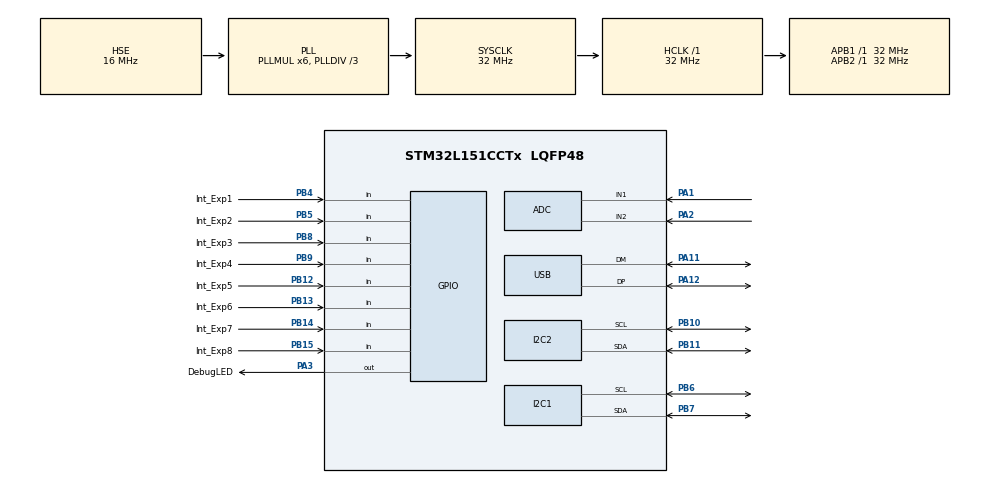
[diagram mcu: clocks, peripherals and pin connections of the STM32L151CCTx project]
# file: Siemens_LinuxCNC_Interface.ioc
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ADC.Channel-0\#ChannelRegularConversion=ADC_CHANNEL_1
ADC.NbrOfConversionFlag=1
ADC.Rank-0\#ChannelRegularConversion=1
ADC.SamplingTime-0\#ChannelRegularConversion=ADC_SAMPLETIME_4CYCLES
I2C2.I2C_Mode=I2C_Standard
Mcu.Family=STM32L1
Mcu.Name=STM32L151CCTx
Mcu.Package=LQFP48
NVIC.PriorityGroup=NVIC_PRIORITYGROUP_4
NVIC.TIM3_IRQn=true\:0\:0\:false\:false\:true\:true\:true\:true
NVIC.USB_LP_IRQn=true\:0\:0\:false\:false\:true\:false\:true\:true
PA1.Mode=IN1
PA1.Signal=ADC_IN1
PA11.Mode=Device
PA11.Signal=USB_DM
PA12.Mode=Device
PA12.Signal=USB_DP
PA13.Mode=JTAG_4_pins
PA13.Signal=SYS_JTMS-SWDIO
PA14.Mode=JTAG_4_pins
PA14.Signal=SYS_JTCK-SWCLK
PA15.Mode=JTAG_4_pins
PA15.Signal=SYS_JTDI
PA2.Mode=IN2
PA2.Signal=ADC_IN2
PA3.GPIO_Label=DebugLED
PA3.Signal=GPIO_Output
PB10.Mode=I2C
PB10.Signal=I2C2_SCL
PB11.Mode=I2C
PB11.Signal=I2C2_SDA
PB12.GPIO_Label=Int_Exp5
PB12.Signal=GPIO_Input
PB13.GPIO_Label=Int_Exp6
PB13.Signal=GPIO_Input
PB14.GPIO_Label=Int_Exp7
PB14.Signal=GPIO_Input
PB15.GPIO_Label=Int_Exp8
PB15.Signal=GPIO_Input
PB3.Mode=JTAG_4_pins
PB3.Signal=SYS_JTDO-TRACESWO
PB4.GPIO_Label=Int_Exp1
PB4.Signal=GPIO_Input
PB5.GPIO_Label=Int_Exp2
PB5.Signal=GPIO_Input
PB6.Mode=I2C
PB6.Signal=I2C1_SCL
PB7.Mode=I2C
PB7.Signal=I2C1_SDA
PB8.GPIO_Label=Int_Exp3
PB8.Signal=GPIO_Input
PB9.GPIO_Label=Int_Exp4
PB9.Signal=GPIO_Input
PH0-OSC_IN.Mode=HSE-External-Oscillator
PH0-OSC_IN.Signal=RCC_OSC_IN
PH1-OSC_OUT.Mode=HSE-External-Oscillator
PH1-OSC_OUT.Signal=RCC_OSC_OUT
ProjectManager.HeapSize=0x200
ProjectManager.StackSize=0x400
ProjectManager.TargetToolchain=STM32CubeIDE
RCC.48MHZClocksFreq_Value=48000000
RCC.AHBFreq_Value=32000000
RCC.APB1Freq_Value=32000000
RCC.APB1TimFreq_Value=32000000
RCC.APB2Freq_Value=32000000
RCC.APB2TimFreq_Value=32000000
RCC.HCLKFreq_Value=32000000
RCC.HSE_VALUE=16000000
RCC.HSI_VALUE=16000000
RCC.LSE_VALUE=32768
RCC.MSI_VALUE=2097000
RCC.PLLDIV=RCC_PLL_DIV3
RCC.PLLMUL=RCC_PLL_MUL6
RCC.SYSCLKFreq_VALUE=32000000
RCC.SYSCLKSource=RCC_SYSCLKSOURCE_PLLCLK
RCC.VCOOutputFreq_Value=96000000
TIM3.AutoReloadPreload=TIM_AUTORELOAD_PRELOAD_ENABLE
TIM3.Period=5000
TIM3.Prescaler=3200
USB_DEVICE.CLASS_NAME_FS=CDC
USB_DEVICE.LANGID_STRING=1031
USB_DEVICE.MANUFACTURER_STRING=Patrick Lermer
USB_DEVICE.PRODUCT_STRING_CDC_FS=Siemens Interface Virtual ComPort
USB_DEVICE.VirtualMode=Cdc
USB_DEVICE.VirtualModeFS=Cdc_FS
VP_TIM3_VS_ClockSourceINT.Mode=Internal
VP_USB_DEVICE_VS_USB_DEVICE_CDC_FS.Mode=CDC_FS
board=custom

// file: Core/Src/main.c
/* USER CODE BEGIN Header */
/**
  ******************************************************************************
  * @file           : main.c
  * @brief          : Main program body
  ******************************************************************************
  * @attention
  *
  * Copyright (c) 2025 STMicroelectronics.
  * All rights reserved.
  *
  * This software is licensed under terms that can be found in the LICENSE file
  * in the root directory of this software component.
  * If no LICENSE file comes with this software, it is provided AS-IS.
  *
  ******************************************************************************
  */
/* USER CODE END Header */
#include "main.h"
#include "usb_device.h"

/* USER CODE BEGIN Includes */
#include "pca9555.c"
/* USER CODE END Includes */

ADC_HandleTypeDef hadc;

I2C_HandleTypeDef hi2c1;
I2C_HandleTypeDef hi2c2;

TIM_HandleTypeDef htim3;

void SystemClock_Config(void);
static void MX_GPIO_Init(void);
static void MX_ADC_Init(void);
static void MX_I2C1_Init(void);
static void MX_I2C2_Init(void);
static void MX_TIM3_Init(void);

int main(void)
{

  /* MCU Configuration--------------------------------------------------------*/

  /* Reset of all peripherals, Initializes the Flash interface and the Systick. */
  HAL_Init();

  /* Configure the system clock */
  SystemClock_Config();

  /* Initialize all configured peripherals */
  MX_GPIO_Init();
  MX_ADC_Init();
  MX_I2C1_Init();
  MX_I2C2_Init();
  MX_USB_DEVICE_Init();
  MX_TIM3_Init();

  /* Infinite loop */
  while (1)
  {

  }
}

void SystemClock_Config(void)
{
  RCC_OscInitTypeDef RCC_OscInitStruct = {0};
  RCC_ClkInitTypeDef RCC_ClkInitStruct = {0};

  /** Configure the main internal regulator output voltage
  */
  __HAL_PWR_VOLTAGESCALING_CONFIG(PWR_REGULATOR_VOLTAGE_SCALE1);

  /** Initializes the RCC Oscillators according to the specified parameters
  * in the RCC_OscInitTypeDef structure.
  */
  RCC_OscInitStruct.OscillatorType = RCC_OSCILLATORTYPE_HSI|RCC_OSCILLATORTYPE_HSE;
  RCC_OscInitStruct.HSEState = RCC_HSE_ON;
  RCC_OscInitStruct.HSIState = RCC_HSI_ON;
  RCC_OscInitStruct.HSICalibrationValue = RCC_HSICALIBRATION_DEFAULT;
  RCC_OscInitStruct.PLL.PLLState = RCC_PLL_ON;
  RCC_OscInitStruct.PLL.PLLSource = RCC_PLLSOURCE_HSE;
  RCC_OscInitStruct.PLL.PLLMUL = RCC_PLL_MUL6;
  RCC_OscInitStruct.PLL.PLLDIV = RCC_PLL_DIV3;
  if (HAL_RCC_OscConfig(&RCC_OscInitStruct) != HAL_OK)
  {
    Error_Handler();
  }

  /** Initializes the CPU, AHB and APB buses clocks
  */
  RCC_ClkInitStruct.ClockType = RCC_CLOCKTYPE_HCLK|RCC_CLOCKTYPE_SYSCLK
                              |RCC_CLOCKTYPE_PCLK1|RCC_CLOCKTYPE_PCLK2;
  RCC_ClkInitStruct.SYSCLKSource = RCC_SYSCLKSOURCE_PLLCLK;
  RCC_ClkInitStruct.AHBCLKDivider = RCC_SYSCLK_DIV1;
  RCC_ClkInitStruct.APB1CLKDivider = RCC_HCLK_DIV1;
  RCC_ClkInitStruct.APB2CLKDivider = RCC_HCLK_DIV1;

  if (HAL_RCC_ClockConfig(&RCC_ClkInitStruct, FLASH_LATENCY_1) != HAL_OK)
  {
    Error_Handler();
  }
}

static void MX_ADC_Init(void)
{

  ADC_ChannelConfTypeDef sConfig = {0};

  /** Configure the global features of the ADC (Clock, Resolution, Data Alignment and number of conversion)
  */
  hadc.Instance = ADC1;
  hadc.Init.ClockPrescaler = ADC_CLOCK_ASYNC_DIV1;
  hadc.Init.Resolution = ADC_RESOLUTION_12B;
  hadc.Init.DataAlign = ADC_DATAALIGN_RIGHT;
  hadc.Init.ScanConvMode = ADC_SCAN_DISABLE;
  hadc.Init.EOCSelection = ADC_EOC_SEQ_CONV;
  hadc.Init.LowPowerAutoWait = ADC_AUTOWAIT_DISABLE;
  hadc.Init.LowPowerAutoPowerOff = ADC_AUTOPOWEROFF_DISABLE;
  hadc.Init.ChannelsBank = ADC_CHANNELS_BANK_A;
  hadc.Init.ContinuousConvMode = DISABLE;
  hadc.Init.NbrOfConversion = 1;
  hadc.Init.DiscontinuousConvMode = DISABLE;
  hadc.Init.ExternalTrigConv = ADC_SOFTWARE_START;
  hadc.Init.ExternalTrigConvEdge = ADC_EXTERNALTRIGCONVEDGE_NONE;
  hadc.Init.DMAContinuousRequests = DISABLE;
  if (HAL_ADC_Init(&hadc) != HAL_OK)
  {
    Error_Handler();
  }

  /** Configure for the selected ADC regular channel its corresponding rank in the sequencer and its sample time.
  */
  sConfig.Channel = ADC_CHANNEL_1;
  sConfig.Rank = ADC_REGULAR_RANK_1;
  sConfig.SamplingTime = ADC_SAMPLETIME_4CYCLES;
  if (HAL_ADC_ConfigChannel(&hadc, &sConfig) != HAL_OK)
  {
    Error_Handler();
  }

}

static void MX_I2C1_Init(void)
{

  hi2c1.Instance = I2C1;
  hi2c1.Init.ClockSpeed = 100000;
  hi2c1.Init.DutyCycle = I2C_DUTYCYCLE_2;
  hi2c1.Init.OwnAddress1 = 0;
  hi2c1.Init.AddressingMode = I2C_ADDRESSINGMODE_7BIT;
  hi2c1.Init.DualAddressMode = I2C_DUALADDRESS_DISABLE;
  hi2c1.Init.OwnAddress2 = 0;
  hi2c1.Init.GeneralCallMode = I2C_GENERALCALL_DISABLE;
  hi2c1.Init.NoStretchMode = I2C_NOSTRETCH_DISABLE;
  if (HAL_I2C_Init(&hi2c1) != HAL_OK)
  {
    Error_Handler();
  }

}

static void MX_I2C2_Init(void)
{

  hi2c2.Instance = I2C2;
  hi2c2.Init.ClockSpeed = 100000;
  hi2c2.Init.DutyCycle = I2C_DUTYCYCLE_2;
  hi2c2.Init.OwnAddress1 = 0;
  hi2c2.Init.AddressingMode = I2C_ADDRESSINGMODE_7BIT;
  hi2c2.Init.DualAddressMode = I2C_DUALADDRESS_DISABLE;
  hi2c2.Init.OwnAddress2 = 0;
  hi2c2.Init.GeneralCallMode = I2C_GENERALCALL_DISABLE;
  hi2c2.Init.NoStretchMode = I2C_NOSTRETCH_DISABLE;
  if (HAL_I2C_Init(&hi2c2) != HAL_OK)
  {
    Error_Handler();
  }

}

static void MX_TIM3_Init(void)
{

  TIM_ClockConfigTypeDef sClockSourceConfig = {0};
  TIM_MasterConfigTypeDef sMasterConfig = {0};

  htim3.Instance = TIM3;
  htim3.Init.Prescaler = 3200;
  htim3.Init.CounterMode = TIM_COUNTERMODE_UP;
  htim3.Init.Period = 5000;
  htim3.Init.ClockDivision = TIM_CLOCKDIVISION_DIV1;
  htim3.Init.AutoReloadPreload = TIM_AUTORELOAD_PRELOAD_ENABLE;
  if (HAL_TIM_Base_Init(&htim3) != HAL_OK)
  {
    Error_Handler();
  }
  sClockSourceConfig.ClockSource = TIM_CLOCKSOURCE_INTERNAL;
  if (HAL_TIM_ConfigClockSource(&htim3, &sClockSourceConfig) != HAL_OK)
  {
    Error_Handler();
  }
  sMasterConfig.MasterOutputTrigger = TIM_TRGO_RESET;
  sMasterConfig.MasterSlaveMode = TIM_MASTERSLAVEMODE_DISABLE;
  if (HAL_TIMEx_MasterConfigSynchronization(&htim3, &sMasterConfig) != HAL_OK)
  {
    Error_Handler();
  }

}

static void MX_GPIO_Init(void)
{
  GPIO_InitTypeDef GPIO_InitStruct = {0};

  /* GPIO Ports Clock Enable */
  __HAL_RCC_GPIOH_CLK_ENABLE();
  __HAL_RCC_GPIOA_CLK_ENABLE();
  __HAL_RCC_GPIOB_CLK_ENABLE();

  /*Configure GPIO pin Output Level */
  HAL_GPIO_WritePin(DebugLED_GPIO_Port, DebugLED_Pin, GPIO_PIN_RESET);

  /*Configure GPIO pin : DebugLED_Pin */
  GPIO_InitStruct.Pin = DebugLED_Pin;
  GPIO_InitStruct.Mode = GPIO_MODE_OUTPUT_PP;
  GPIO_InitStruct.Pull = GPIO_NOPULL;
  GPIO_InitStruct.Speed = GPIO_SPEED_FREQ_LOW;
  HAL_GPIO_Init(DebugLED_GPIO_Port, &GPIO_InitStruct);

  /*Configure GPIO pins : Int_Exp5_Pin Int_Exp6_Pin Int_Exp7_Pin Int_Exp8_Pin
                           Int_Exp1_Pin Int_Exp2_Pin Int_Exp3_Pin Int_Exp4_Pin */
  GPIO_InitStruct.Pin = Int_Exp5_Pin|Int_Exp6_Pin|Int_Exp7_Pin|Int_Exp8_Pin
                          |Int_Exp1_Pin|Int_Exp2_Pin|Int_Exp3_Pin|Int_Exp4_Pin;
  GPIO_InitStruct.Mode = GPIO_MODE_INPUT;
  GPIO_InitStruct.Pull = GPIO_NOPULL;
  HAL_GPIO_Init(GPIOB, &GPIO_InitStruct);

}

void Error_Handler(void)
{
  __disable_irq();
  while (1)
  {
  }
}
